# dm648_cslr_tsip_001 register map
Vendor: Texas Instruments
Peripheral module from a debugger description file.
Registers are 32-bit, read-write, reset 0x0 unless marked. A register's access mark holds for its fields unless they carry their own. Offsets are as the file gives them; lines under a group give offsets from that group; [hi:lo] are bit positions; {n}, {i} and the like mark numbered series; 'fields as' and 'values as' point back to an identical list; <NAME> marks a mode.

## TSIP — TSIP MODULE REGISTERS
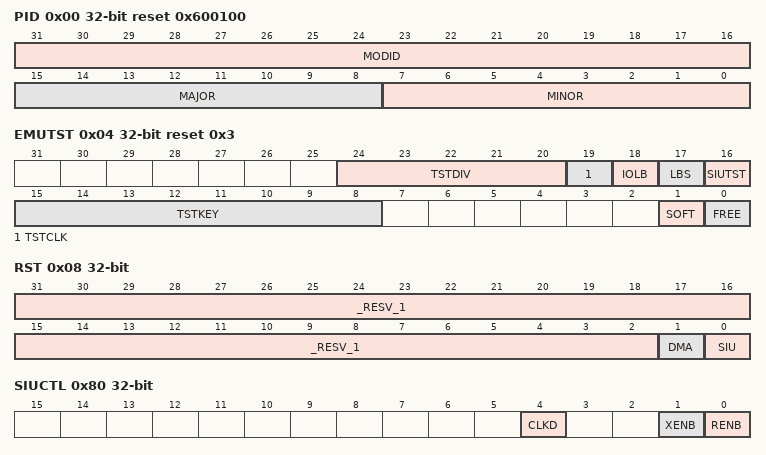
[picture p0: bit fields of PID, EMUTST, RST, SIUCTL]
0x00 PID ro reset 0x600100 — Peripheral Identification
  [31:16] MODID — Module Id
  [15:8] MAJOR — Major Version Value
  [7:0] MINOR — Minor Version Value
0x04 EMUTST access not given reset 0x3 — Emulation and Test Register
  [24:20] TSTDIV rw — Internal Test Clock Divider Ratio
  [19] TSTCLK rw — Test Clock Source Selection
  [18] IOLB rw — Serial Test mode selection
  [17] LBS rw — Serial Test mode selection
  [16] SIUTST rw — Number of MP and Shadow regions
  [15:8] TSTKEY rw — Test key
  [1] SOFT rw — Soft run selection
  [0] FREE rw — Free run selection
0x08 RST access not given — Reset Register
  [31:2] _RESV_1 — Rserved (access N)
  [1] DMA rw — TDMU and DMATCU Reset
    1=RST
  [0] SIU rw — SIU Reset
    1=RST
0x80 SIUCTL access not given — SIU Global Control Register
  [4] CLKD rw — Clock Reduncy Selection
  [1] XENB rw — Receive Enable
    1=ENB; 0=DIS
  [0] RENB rw — Transmit Enable
    1=ENB; 0=DIS
0xA0 XCLK access not given — Transmit Clock Source Register
  [0] SRC rw — Transmit clock and frame sync selection
    0=ACLK; 1=BCLK
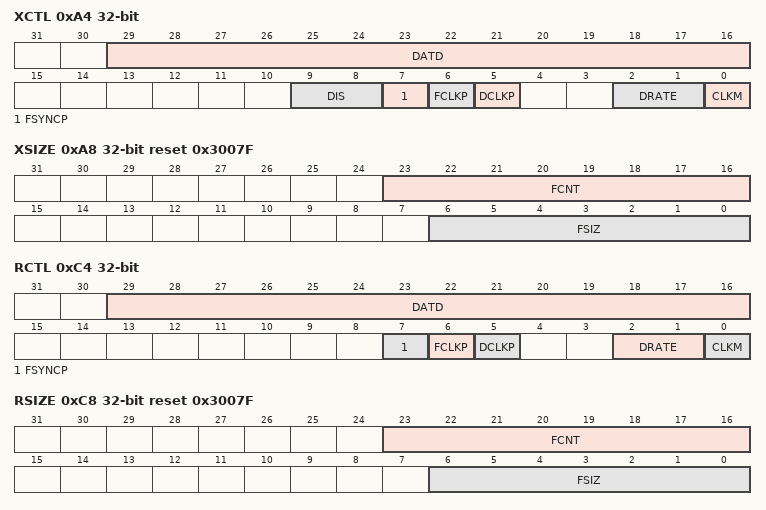
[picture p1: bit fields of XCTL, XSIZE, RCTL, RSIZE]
0xA4 XCTL access not given — Transmit Control Register
  [29:16] DATD rw — Transmit data delay
  [9:8] DIS rw — Transmit output disable state
    0=HIMPED; 2=LOW; 3=HIGH
  [7] FSYNCP rw — Transmit frame sync polarity
    0=ALOW; 1=AHIGH
  [6] FCLKP rw — Transmit frame sync clock polarity
    0=RISING; 1=FALLING
  [5] DCLKP rw — Transmit data clock polarity
    0=RISING; 1=FALLING
  [2:1] DRATE rw — Transmit data rate
    0=8M; 1=16M; 2=32M
  [0] CLKM rw — Transmit clock mode
    0=DBL; 1=SGL
0xA8 XSIZE access not given reset 0x3007F — Transmit Size Register
  [23:16] FCNT rw — Transmit Frame count
  [6:0] FSIZ rw — Transmit Frame Size
0xC0 RCLK access not given — Receive Clock Source Register
  [0] SRC rw — Receive clocl and frame sync selection
    0=ACLK; 1=BCLK
0xC4 RCTL access not given — Receive Control Register
  [29:16] DATD rw — Receive data delay
  [7] FSYNCP rw — Receive frame sync polarity
    0=ALOW; 1=AHIGH
  [6] FCLKP rw — Receive frame sync clock polarity
    0=RISING; 1=FALLING
  [5] DCLKP rw — Receive data clock polarity
    0=RISING; 1=FALLING
  [2:1] DRATE rw — Receive Data rate
    0=8M; 1=16M; 2=32M
  [0] CLKM rw — Receive clock mode
    0=DBL; 1=SGL
0xC8 RSIZE access not given reset 0x3007F — Receive size registers
  [23:16] FCNT rw — Receive frame count
  [6:0] FSIZ rw — Receive frme size
0x100 TDMUCTL access not given — TDMU Global Control Register
  [0] DMAENB rw — TDMU and DMATCU enable
    1=ENB; 0=DIS
0x104 XFRFC access not given — Transmit Free Running Frame Counter
  [23:0] FRFC ro — Free Running Frame Counter
0x108 RFRFC access not given — Receive Free Running Frame Counter
  [23:0] FRFC ro — Free Running Frame Counter
0x10C TDMUCFG access not given — TDMU Global Configuration Register
  [0] BEND rw — Endian Mode Selection
    0=LITTLE; 1=BIG
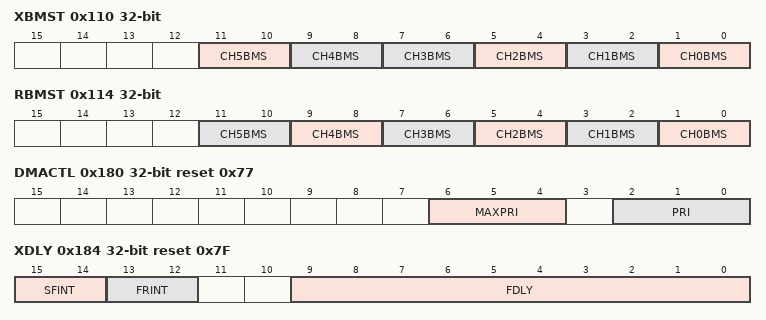
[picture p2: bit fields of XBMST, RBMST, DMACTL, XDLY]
0x110 XBMST access not given — Transmit Channel Bitmap Active Status Register
  [11:10] CH5BMS ro — Transmit Channel 5 active status
  [9:8] CH4BMS ro — Transmit chaneel 4 active status
  [2n+1:2n] CH{n}BMS ro (n=0..3) — Transmit channel {n} active status
0x114 RBMST access not given — Receive Channel Bitmap Active Status Register
  [2n+1:2n] CH{n}BMS ro (n=0..5) — Receive Channel {n} status
0x180 DMACTL access not given reset 0x77 — DMATCU Global Control Register
  [6:4] MAXPRI rw — Maximum Transfer Priority
  [2:0] PRI rw — Transfer Priority
0x184 XDLY access not given reset 0x7F — Transmit timeslot delay counter
  [15:14] SFINT ro — Transmit Superframe interrupt selection
    0=ACK; 1=DLY; 2=ACKORDLY; 3=ACKNDLY
  [13:12] FRINT ro — Transmit Frame interrupt selection
    0=ACK; 1=DLY; 2=ACKORDLY; 3=ACKNDLY
  [9:0] FDLY rw — Transmit frame interrupt delay
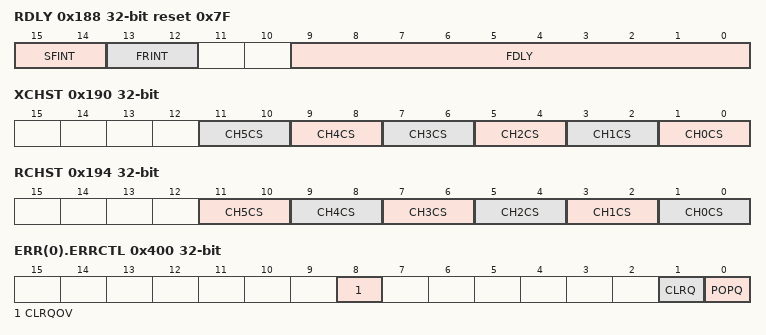
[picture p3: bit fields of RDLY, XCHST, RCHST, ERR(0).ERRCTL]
0x188 RDLY access not given reset 0x7F — Receive Timeslot Delay Counter
  [15:14] SFINT ro — Receive superframe interrupt selection
    0=ACK; 1=DLY; 2=ACKORDLY; 3=ACKNDLY
  [13:12] FRINT ro — Receive Frame interrupt selection
    0=ACK; 1=DLY; 2=ACKORDLY; 3=ACKNDLY
  [9:0] FDLY rw — Receive frame interrupt delay
0x190 XCHST access not given — Transmit channel Configuration active status register
  [2n+1:2n] CH{n}CS ro (n=0..5) — Transmit channel {n} active status
0x194 RCHST access not given — Receive channel Configuration active status register
  [11:10] CH5CS ro — Receive channel 5 active status
  [9:8] CH4CS ro — Receive channel 4 active status
  [7:6] CH3CS ro — Receiev channel 3 active status
  [5:4] CH2CS ro — Receive channel 2 active status
  [3:2] CH1CS ro — Receive channel 1 active status
  [1:0] CH0CS ro — Receive channel 0 active status
0x400 ERR(0).ERRCTL access not given — Transmit/Receive channel error control register {ERR_CTL}
  [8] CLRQOV rw — Clear error queue overflow flag
    1=CLR
  [1] CLRQ rw — Clear error queue
    1=CLR
  [0] POPQ rw — Pop the top entity off the error queue
    1=POP
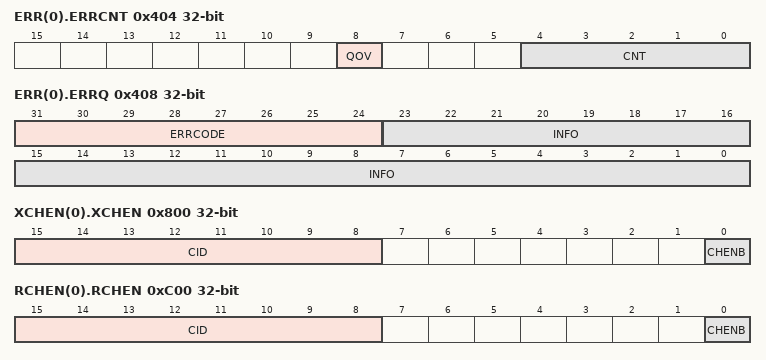
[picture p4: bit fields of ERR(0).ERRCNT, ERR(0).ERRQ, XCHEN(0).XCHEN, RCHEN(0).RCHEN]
0x404 ERR(0).ERRCNT access not given — Transmit/Receive channel error count register {ERR_CNT}
  [8] QOV ro — Error queue overflow
  [4:0] CNT ro — Error count
0x408 ERR(0).ERRQ ro — Transmit/Receive channel error queue register
  [31:24] ERRCODE — Error Code
  [23:0] INFO — Error information field
0x800 XCHEN(0).XCHEN access not given — TDMU Transmit Channel Enable Register {XCHEN(0).XCHEN_XCHEN(0).XCHEN}
  [15:8] CID rw — configuration Identification
  [0] CHENB rw — Channel n enable
    1=ENB; 0=DIS
0xC00 RCHEN(0).RCHEN access not given — TDMU Receive Channel Enable Register {RCHEN(0).RCHEN_RCHEN(0).RCHEN}
  fields as XCHEN(0).XCHEN
0x1000 DXCH(0).ABASE — DMATCU Transmit Channel Memory Base Address Register A {DXCH_DXCH(0).ABASE}
  [31:0] ADDR — Memory Buffer Base Address
0x1004 DXCH(0).AFALLOC access not given — DMATCU Transmit Channel Frame Allocation Register A {DXCH_DXCH(0).AFALLOC}
  [11:0] FALLOC rw — Frame Buffer Allocation
0x1008 DXCH(0).AFSIZE access not given — DMATCU Transmit Channel Frame Size Register A {DXCH_DXCH(0).AFSIZE}
  [11:0] FSIZE rw — Frame Size
0x100C DXCH(0).AFCNT access not given — DMATCU Transmit Channel Frame Count Register A {DXCH_DXCH(0).AFCNT}
  [7:0] FCOUNT rw — Frame count
0x1014 DXCH(0).BBASE — DMATCU Transmit Channel Memory Base Address Register B {DXCH_DXCH(0).BBASE}
  [31:0] ADDR — Memory Buffer Base Address
0x1018 DXCH(0).BFALLOC access not given — DMATCU Transmit Channel Frame Allocation Register B {DXCH_DXCH(0).BFALLOC}
  [11:0] FALLOC rw — Frame Buffer Allocation
0x101C DXCH(0).BFSIZE access not given — DMATCU Transmit Channel Frame Size Register B {DXCH_BSIZE}
  [11:0] FSIZE rw — Frame Size
0x1020 DXCH(0).BFCNT access not given — DMATCU Transmit Channel Frame Count Register B {DXCH_DXCH(0).BFCNT}
  [7:0] FCOUNT rw — Frame count
0x1800 DRCH(0).ABASE — DMATCU Receive Channel Memory Base Address Register A {DRCH_DRCH(0).ABASE}
  [31:0] ADDR — Memory Buffer Base Address
0x1804 DRCH(0).AFALLOC access not given — DMATCU Receive Channel Frame Allocation Register A {DRCH_DRCH(0).AFALLOC}
  [11:0] FALLOC rw — Frame Buffer Allocation
0x1808 DRCH(0).AFSIZE access not given — DMATCU Receive Channel Frame Size Register A {DRCH_DRCH(0).AFSIZE}
  [11:0] FSIZE rw — Frame Size
0x180C DRCH(0).AFCNT access not given — DMATCU Receive Channel Frame Count Register A {DRCH_DRCH(0).AFCNT}
  [7:0] FCOUNT rw — Frame count
0x1814 DRCH(0).BBASE — DMATCU Receive Channel Memory Base Address Register B {DRCH_DRCH(0).BBASE}
  [31:0] ADDR — Memory Buffer Base Address
0x1818 DRCH(0).BFALLOC access not given — DMATCU Receive Channel Frame Allocation Register B {DRCH_DRCH(0).BFALLOC}
  [11:0] FALLOC rw — Frame Buffer Allocation
0x181C DRCH(0).BFSIZE access not given — DMATCU Receive Channel Frame Size Register B {DRCH_DRCH(0).BFSIZE}
  [11:0] FSIZE rw — Frame Size
0x1820 DRCH(0).BFCNT access not given — DMATCU Receive Channel Frame Count Register B {DRCH_DRCH(0).BFCNT}
  [7:0] FCOUNT rw — Frame count
0x8000 XBM(0).XBMA(0) — Transmit Channel Bitmap A {XBM_XBM(0).XBMA}
  [31:0] CH — Reserved
0x8004 XBM(0).XBMA(1) — Transmit Channel Bitmap A {XBM_XBM(0).XBMA}
  [31:0] CH — Reserved
0x8008 XBM(0).XBMA(2) — Transmit Channel Bitmap A {XBM_XBM(0).XBMA}
  [31:0] CH — Reserved
0x800C XBM(0).XBMA(3) — Transmit Channel Bitmap A {XBM_XBM(0).XBMA}
  [31:0] CH — Reserved
0x8010 XBM(0).XBMA(4) — Transmit Channel Bitmap A {XBM_XBM(0).XBMA}
  [31:0] CH — Reserved
0x8014 XBM(0).XBMA(5) — Transmit Channel Bitmap A {XBM_XBM(0).XBMA}
  [31:0] CH — Reserved
0x8018 XBM(0).XBMA(6) — Transmit Channel Bitmap A {XBM_XBM(0).XBMA}
  [31:0] CH — Reserved
0x801C XBM(0).XBMA(7) — Transmit Channel Bitmap A {XBM_XBM(0).XBMA}
  [31:0] CH — Reserved
0x8020 XBM(0).XBMA(8) — Transmit Channel Bitmap A {XBM_XBM(0).XBMA}
  [31:0] CH — Reserved
0x8024 XBM(0).XBMA(9) — Transmit Channel Bitmap A {XBM_XBM(0).XBMA}
  [31:0] CH — Reserved
0x8028 XBM(0).XBMA(10) — Transmit Channel Bitmap A {XBM_XBM(0).XBMA}
  [31:0] CH — Reserved
0x802C XBM(0).XBMA(11) — Transmit Channel Bitmap A {XBM_XBM(0).XBMA}
  [31:0] CH — Reserved
0x8030 XBM(0).XBMA(12) — Transmit Channel Bitmap A {XBM_XBM(0).XBMA}
  [31:0] CH — Reserved
0x8034 XBM(0).XBMA(13) — Transmit Channel Bitmap A {XBM_XBM(0).XBMA}
  [31:0] CH — Reserved
0x8038 XBM(0).XBMA(14) — Transmit Channel Bitmap A {XBM_XBM(0).XBMA}
  [31:0] CH — Reserved
0x803C XBM(0).XBMA(15) — Transmit Channel Bitmap A {XBM_XBM(0).XBMA}
  [31:0] CH — Reserved
0x8040 XBM(0).XBMA(16) — Transmit Channel Bitmap A {XBM_XBM(0).XBMA}
  [31:0] CH — Reserved
0x8044 XBM(0).XBMA(17) — Transmit Channel Bitmap A {XBM_XBM(0).XBMA}
  [31:0] CH — Reserved
0x8048 XBM(0).XBMA(18) — Transmit Channel Bitmap A {XBM_XBM(0).XBMA}
  [31:0] CH — Reserved
0x804C XBM(0).XBMA(19) — Transmit Channel Bitmap A {XBM_XBM(0).XBMA}
  [31:0] CH — Reserved
0x8050 XBM(0).XBMA(20) — Transmit Channel Bitmap A {XBM_XBM(0).XBMA}
  [31:0] CH — Reserved
0x8054 XBM(0).XBMA(21) — Transmit Channel Bitmap A {XBM_XBM(0).XBMA}
  [31:0] CH — Reserved
0x8058 XBM(0).XBMA(22) — Transmit Channel Bitmap A {XBM_XBM(0).XBMA}
  [31:0] CH — Reserved
0x805C XBM(0).XBMA(23) — Transmit Channel Bitmap A {XBM_XBM(0).XBMA}
  [31:0] CH — Reserved
0x8060 XBM(0).XBMA(24) — Transmit Channel Bitmap A {XBM_XBM(0).XBMA}
  [31:0] CH — Reserved
0x8064 XBM(0).XBMA(25) — Transmit Channel Bitmap A {XBM_XBM(0).XBMA}
  [31:0] CH — Reserved
0x8068 XBM(0).XBMA(26) — Transmit Channel Bitmap A {XBM_XBM(0).XBMA}
  [31:0] CH — Reserved
0x806C XBM(0).XBMA(27) — Transmit Channel Bitmap A {XBM_XBM(0).XBMA}
  [31:0] CH — Reserved
0x8070 XBM(0).XBMA(28) — Transmit Channel Bitmap A {XBM_XBM(0).XBMA}
  [31:0] CH — Reserved
0x8074 XBM(0).XBMA(29) — Transmit Channel Bitmap A {XBM_XBM(0).XBMA}
  [31:0] CH — Reserved
0x8078 XBM(0).XBMA(30) — Transmit Channel Bitmap A {XBM_XBM(0).XBMA}
  [31:0] CH — Reserved
0x807C XBM(0).XBMA(31) — Transmit Channel Bitmap A {XBM_XBM(0).XBMA}
  [31:0] CH — Reserved
0x8080 XBM(0).XBMA(32) — Transmit Channel Bitmap A {XBM_XBM(0).XBMA}
  [31:0] CH — Reserved
0x8084 XBM(0).XBMA(33) — Transmit Channel Bitmap A {XBM_XBM(0).XBMA}
  [31:0] CH — Reserved
0x8088 XBM(0).XBMA(34) — Transmit Channel Bitmap A {XBM_XBM(0).XBMA}
  [31:0] CH — Reserved
0x808C XBM(0).XBMA(35) — Transmit Channel Bitmap A {XBM_XBM(0).XBMA}
  [31:0] CH — Reserved
0x8090 XBM(0).XBMA(36) — Transmit Channel Bitmap A {XBM_XBM(0).XBMA}
  [31:0] CH — Reserved
0x8094 XBM(0).XBMA(37) — Transmit Channel Bitmap A {XBM_XBM(0).XBMA}
  [31:0] CH — Reserved
0x8098 XBM(0).XBMA(38) — Transmit Channel Bitmap A {XBM_XBM(0).XBMA}
  [31:0] CH — Reserved
0x809C XBM(0).XBMA(39) — Transmit Channel Bitmap A {XBM_XBM(0).XBMA}
  [31:0] CH — Reserved
0x80A0 XBM(0).XBMA(40) — Transmit Channel Bitmap A {XBM_XBM(0).XBMA}
  [31:0] CH — Reserved
0x80A4 XBM(0).XBMA(41) — Transmit Channel Bitmap A {XBM_XBM(0).XBMA}
  [31:0] CH — Reserved
0x80A8 XBM(0).XBMA(42) — Transmit Channel Bitmap A {XBM_XBM(0).XBMA}
  [31:0] CH — Reserved
0x80AC XBM(0).XBMA(43) — Transmit Channel Bitmap A {XBM_XBM(0).XBMA}
  [31:0] CH — Reserved
0x80B0 XBM(0).XBMA(44) — Transmit Channel Bitmap A {XBM_XBM(0).XBMA}
  [31:0] CH — Reserved
0x80B4 XBM(0).XBMA(45) — Transmit Channel Bitmap A {XBM_XBM(0).XBMA}
  [31:0] CH — Reserved
0x80B8 XBM(0).XBMA(46) — Transmit Channel Bitmap A {XBM_XBM(0).XBMA}
  [31:0] CH — Reserved
0x80BC XBM(0).XBMA(47) — Transmit Channel Bitmap A {XBM_XBM(0).XBMA}
  [31:0] CH — Reserved
0x80C0 XBM(0).XBMA(48) — Transmit Channel Bitmap A {XBM_XBM(0).XBMA}
  [31:0] CH — Reserved
0x80C4 XBM(0).XBMA(49) — Transmit Channel Bitmap A {XBM_XBM(0).XBMA}
  [31:0] CH — Reserved
0x80C8 XBM(0).XBMA(50) — Transmit Channel Bitmap A {XBM_XBM(0).XBMA}
  [31:0] CH — Reserved
0x80CC XBM(0).XBMA(51) — Transmit Channel Bitmap A {XBM_XBM(0).XBMA}
  [31:0] CH — Reserved
0x80D0 XBM(0).XBMA(52) — Transmit Channel Bitmap A {XBM_XBM(0).XBMA}
  [31:0] CH — Reserved
0x80D4 XBM(0).XBMA(53) — Transmit Channel Bitmap A {XBM_XBM(0).XBMA}
  [31:0] CH — Reserved
0x80D8 XBM(0).XBMA(54) — Transmit Channel Bitmap A {XBM_XBM(0).XBMA}
  [31:0] CH — Reserved
0x80DC XBM(0).XBMA(55) — Transmit Channel Bitmap A {XBM_XBM(0).XBMA}
  [31:0] CH — Reserved
0x80E0 XBM(0).XBMA(56) — Transmit Channel Bitmap A {XBM_XBM(0).XBMA}
  [31:0] CH — Reserved
0x80E4 XBM(0).XBMA(57) — Transmit Channel Bitmap A {XBM_XBM(0).XBMA}
  [31:0] CH — Reserved
0x80E8 XBM(0).XBMA(58) — Transmit Channel Bitmap A {XBM_XBM(0).XBMA}
  [31:0] CH — Reserved
0x80EC XBM(0).XBMA(59) — Transmit Channel Bitmap A {XBM_XBM(0).XBMA}
  [31:0] CH — Reserved
0x80F0 XBM(0).XBMA(60) — Transmit Channel Bitmap A {XBM_XBM(0).XBMA}
  [31:0] CH — Reserved
0x80F4 XBM(0).XBMA(61) — Transmit Channel Bitmap A {XBM_XBM(0).XBMA}
  [31:0] CH — Reserved
0x80F8 XBM(0).XBMA(62) — Transmit Channel Bitmap A {XBM_XBM(0).XBMA}
  [31:0] CH — Reserved
0x80FC XBM(0).XBMA(63) — Transmit Channel Bitmap A {XBM_XBM(0).XBMA}
  [31:0] CH — Reserved
0x8100 XBM(0).XBMB(0) — Transmit Channel Bitmap B {XBM_XBM(0).XBMB}
  [31:0] CH — Reserved
0x8104 XBM(0).XBMB(1) — Transmit Channel Bitmap B {XBM_XBM(0).XBMB}
  [31:0] CH — Reserved
0x8108 XBM(0).XBMB(2) — Transmit Channel Bitmap B {XBM_XBM(0).XBMB}
  [31:0] CH — Reserved
0x810C XBM(0).XBMB(3) — Transmit Channel Bitmap B {XBM_XBM(0).XBMB}
  [31:0] CH — Reserved
0x8110 XBM(0).XBMB(4) — Transmit Channel Bitmap B {XBM_XBM(0).XBMB}
  [31:0] CH — Reserved
0x8114 XBM(0).XBMB(5) — Transmit Channel Bitmap B {XBM_XBM(0).XBMB}
  [31:0] CH — Reserved
0x8118 XBM(0).XBMB(6) — Transmit Channel Bitmap B {XBM_XBM(0).XBMB}
  [31:0] CH — Reserved
0x811C XBM(0).XBMB(7) — Transmit Channel Bitmap B {XBM_XBM(0).XBMB}
  [31:0] CH — Reserved
0x8120 XBM(0).XBMB(8) — Transmit Channel Bitmap B {XBM_XBM(0).XBMB}
  [31:0] CH — Reserved
0x8124 XBM(0).XBMB(9) — Transmit Channel Bitmap B {XBM_XBM(0).XBMB}
  [31:0] CH — Reserved
0x8128 XBM(0).XBMB(10) — Transmit Channel Bitmap B {XBM_XBM(0).XBMB}
  [31:0] CH — Reserved
0x812C XBM(0).XBMB(11) — Transmit Channel Bitmap B {XBM_XBM(0).XBMB}
  [31:0] CH — Reserved
0x8130 XBM(0).XBMB(12) — Transmit Channel Bitmap B {XBM_XBM(0).XBMB}
  [31:0] CH — Reserved
0x8134 XBM(0).XBMB(13) — Transmit Channel Bitmap B {XBM_XBM(0).XBMB}
  [31:0] CH — Reserved
0x8138 XBM(0).XBMB(14) — Transmit Channel Bitmap B {XBM_XBM(0).XBMB}
  [31:0] CH — Reserved
0x813C XBM(0).XBMB(15) — Transmit Channel Bitmap B {XBM_XBM(0).XBMB}
  [31:0] CH — Reserved
0x8140 XBM(0).XBMB(16) — Transmit Channel Bitmap B {XBM_XBM(0).XBMB}
  [31:0] CH — Reserved
0x8144 XBM(0).XBMB(17) — Transmit Channel Bitmap B {XBM_XBM(0).XBMB}
  [31:0] CH — Reserved
0x8148 XBM(0).XBMB(18) — Transmit Channel Bitmap B {XBM_XBM(0).XBMB}
  [31:0] CH — Reserved
0x814C XBM(0).XBMB(19) — Transmit Channel Bitmap B {XBM_XBM(0).XBMB}
  [31:0] CH — Reserved
0x8150 XBM(0).XBMB(20) — Transmit Channel Bitmap B {XBM_XBM(0).XBMB}
  [31:0] CH — Reserved
0x8154 XBM(0).XBMB(21) — Transmit Channel Bitmap B {XBM_XBM(0).XBMB}
  [31:0] CH — Reserved
0x8158 XBM(0).XBMB(22) — Transmit Channel Bitmap B {XBM_XBM(0).XBMB}
  [31:0] CH — Reserved
0x815C XBM(0).XBMB(23) — Transmit Channel Bitmap B {XBM_XBM(0).XBMB}
  [31:0] CH — Reserved
0x8160 XBM(0).XBMB(24) — Transmit Channel Bitmap B {XBM_XBM(0).XBMB}
  [31:0] CH — Reserved
0x8164 XBM(0).XBMB(25) — Transmit Channel Bitmap B {XBM_XBM(0).XBMB}
  [31:0] CH — Reserved
0x8168 XBM(0).XBMB(26) — Transmit Channel Bitmap B {XBM_XBM(0).XBMB}
  [31:0] CH — Reserved
0x816C XBM(0).XBMB(27) — Transmit Channel Bitmap B {XBM_XBM(0).XBMB}
  [31:0] CH — Reserved
0x8170 XBM(0).XBMB(28) — Transmit Channel Bitmap B {XBM_XBM(0).XBMB}
  [31:0] CH — Reserved
0x8174 XBM(0).XBMB(29) — Transmit Channel Bitmap B {XBM_XBM(0).XBMB}
  [31:0] CH — Reserved
0x8178 XBM(0).XBMB(30) — Transmit Channel Bitmap B {XBM_XBM(0).XBMB}
  [31:0] CH — Reserved
0x817C XBM(0).XBMB(31) — Transmit Channel Bitmap B {XBM_XBM(0).XBMB}
  [31:0] CH — Reserved
0x8180 XBM(0).XBMB(32) — Transmit Channel Bitmap B {XBM_XBM(0).XBMB}
  [31:0] CH — Reserved
0x8184 XBM(0).XBMB(33) — Transmit Channel Bitmap B {XBM_XBM(0).XBMB}
  [31:0] CH — Reserved
0x8188 XBM(0).XBMB(34) — Transmit Channel Bitmap B {XBM_XBM(0).XBMB}
  [31:0] CH — Reserved
0x818C XBM(0).XBMB(35) — Transmit Channel Bitmap B {XBM_XBM(0).XBMB}
  [31:0] CH — Reserved
0x8190 XBM(0).XBMB(36) — Transmit Channel Bitmap B {XBM_XBM(0).XBMB}
  [31:0] CH — Reserved
0x8194 XBM(0).XBMB(37) — Transmit Channel Bitmap B {XBM_XBM(0).XBMB}
  [31:0] CH — Reserved
0x8198 XBM(0).XBMB(38) — Transmit Channel Bitmap B {XBM_XBM(0).XBMB}
  [31:0] CH — Reserved
0x819C XBM(0).XBMB(39) — Transmit Channel Bitmap B {XBM_XBM(0).XBMB}
  [31:0] CH — Reserved
0x81A0 XBM(0).XBMB(40) — Transmit Channel Bitmap B {XBM_XBM(0).XBMB}
  [31:0] CH — Reserved
0x81A4 XBM(0).XBMB(41) — Transmit Channel Bitmap B {XBM_XBM(0).XBMB}
  [31:0] CH — Reserved
0x81A8 XBM(0).XBMB(42) — Transmit Channel Bitmap B {XBM_XBM(0).XBMB}
  [31:0] CH — Reserved
0x81AC XBM(0).XBMB(43) — Transmit Channel Bitmap B {XBM_XBM(0).XBMB}
  [31:0] CH — Reserved
0x81B0 XBM(0).XBMB(44) — Transmit Channel Bitmap B {XBM_XBM(0).XBMB}
  [31:0] CH — Reserved
0x81B4 XBM(0).XBMB(45) — Transmit Channel Bitmap B {XBM_XBM(0).XBMB}
  [31:0] CH — Reserved
0x81B8 XBM(0).XBMB(46) — Transmit Channel Bitmap B {XBM_XBM(0).XBMB}
  [31:0] CH — Reserved
0x81BC XBM(0).XBMB(47) — Transmit Channel Bitmap B {XBM_XBM(0).XBMB}
  [31:0] CH — Reserved
0x81C0 XBM(0).XBMB(48) — Transmit Channel Bitmap B {XBM_XBM(0).XBMB}
  [31:0] CH — Reserved
0x81C4 XBM(0).XBMB(49) — Transmit Channel Bitmap B {XBM_XBM(0).XBMB}
  [31:0] CH — Reserved
0x81C8 XBM(0).XBMB(50) — Transmit Channel Bitmap B {XBM_XBM(0).XBMB}
  [31:0] CH — Reserved
0x81CC XBM(0).XBMB(51) — Transmit Channel Bitmap B {XBM_XBM(0).XBMB}
  [31:0] CH — Reserved
0x81D0 XBM(0).XBMB(52) — Transmit Channel Bitmap B {XBM_XBM(0).XBMB}
  [31:0] CH — Reserved
0x81D4 XBM(0).XBMB(53) — Transmit Channel Bitmap B {XBM_XBM(0).XBMB}
  [31:0] CH — Reserved
0x81D8 XBM(0).XBMB(54) — Transmit Channel Bitmap B {XBM_XBM(0).XBMB}
  [31:0] CH — Reserved
0x81DC XBM(0).XBMB(55) — Transmit Channel Bitmap B {XBM_XBM(0).XBMB}
  [31:0] CH — Reserved
0x81E0 XBM(0).XBMB(56) — Transmit Channel Bitmap B {XBM_XBM(0).XBMB}
  [31:0] CH — Reserved
0x81E4 XBM(0).XBMB(57) — Transmit Channel Bitmap B {XBM_XBM(0).XBMB}
  [31:0] CH — Reserved
0x81E8 XBM(0).XBMB(58) — Transmit Channel Bitmap B {XBM_XBM(0).XBMB}
  [31:0] CH — Reserved
0x81EC XBM(0).XBMB(59) — Transmit Channel Bitmap B {XBM_XBM(0).XBMB}
  [31:0] CH — Reserved
0x81F0 XBM(0).XBMB(60) — Transmit Channel Bitmap B {XBM_XBM(0).XBMB}
  [31:0] CH — Reserved
0x81F4 XBM(0).XBMB(61) — Transmit Channel Bitmap B {XBM_XBM(0).XBMB}
  [31:0] CH — Reserved
0x81F8 XBM(0).XBMB(62) — Transmit Channel Bitmap B {XBM_XBM(0).XBMB}
  [31:0] CH — Reserved
0x81FC XBM(0).XBMB(63) — Transmit Channel Bitmap B {XBM_XBM(0).XBMB}
  [31:0] CH — Reserved
{0xC000+4i} RBM(0).RBMA({i}) (i=0..63) — Receive Channel Bitmap A
  [31:0] CH — Reserved
{0xC100+4i} RBM(0).RBMB({i}) (i=0..63) — Receive Channel Bitmap B
  [31:0] CH — Reserved
0x10000 XPING0 — Transmit Channel 0 Ping buffer
  [31:0] DAT — Reserved
0x10400 XPONG0 — Transmit Channel 0 Pong buffer
  [31:0] DAT — Reserved
0x18000 RPING0 — Receive Channel 0 Ping buffer
  [31:0] DAT — Reserved
0x18400 RPONG0 — Receive Channel 0 Pong buffer
  [31:0] DAT — Reserved
